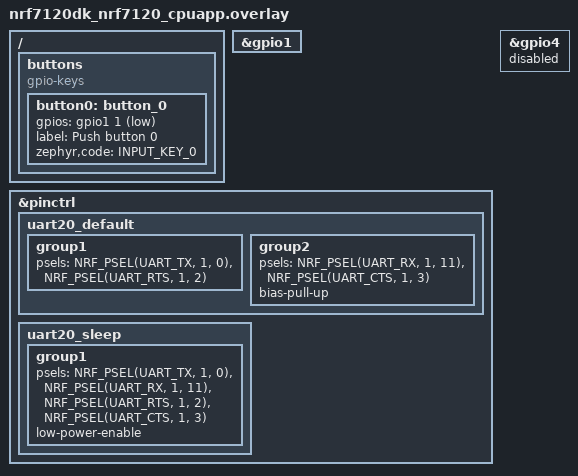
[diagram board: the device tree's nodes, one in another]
/*
 * Copyright (c) 2026 Nordic Semiconductor ASA
 *
 * SPDX-License-Identifier: LicenseRef-Nordic-5-Clause
 */

/ {
	/*
	 * Redefine sw0/button0 to use RXD0 - P1.01
	 * Thus, when sending character from host, there will be gpio interrupt,
	 * the same as originally triggered by sw0 button.
	 */
	buttons {
		compatible = "gpio-keys";

		button0: button_0 {
			gpios = <&gpio1 1 (GPIO_PULL_UP | GPIO_ACTIVE_LOW)>;
			label = "Push button 0";
			zephyr,code = <INPUT_KEY_0>;
		};
	};
};

&gpio1 {
	status = "okay";
};

&pinctrl {
	/*
	 * Redefine: RXD0 -> P1.11
	 */
	/omit-if-no-ref/ uart20_default: uart20_default {
		group1 {
			psels = <NRF_PSEL(UART_TX, 1, 0)>,
				<NRF_PSEL(UART_RTS, 1, 2)>;
		};

		group2 {
			psels = <NRF_PSEL(UART_RX, 1, 11)>,
				<NRF_PSEL(UART_CTS, 1, 3)>;
			bias-pull-up;
		};
	};

	/omit-if-no-ref/ uart20_sleep: uart20_sleep {
		group1 {
			psels = <NRF_PSEL(UART_TX, 1, 0)>,
				<NRF_PSEL(UART_RX, 1, 11)>,
				<NRF_PSEL(UART_RTS, 1, 2)>,
				<NRF_PSEL(UART_CTS, 1, 3)>;
			low-power-enable;
		};
	};
};

&gpio4 {
	status = "disabled";
};
